AUTOSAR XML (schema 00048)
package /HuaweiMDC/PlatformApplication/FmLibApplication/Execution
  executable fm_lib
    root sw component prototype fm_lib: application-type=fm_lib
package /HuaweiMDC/PlatformApplication/FmLibApplication/SwcComponent
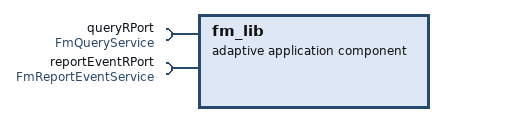
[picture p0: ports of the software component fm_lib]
  adaptive application sw component type fm_lib
    require port queryRPort: required-interface=FmQueryService
    require port reportEventRPort: required-interface=FmReportEventService
